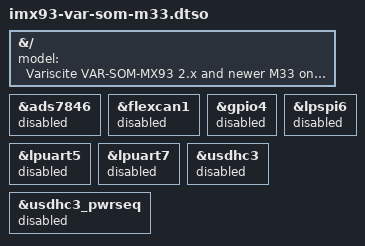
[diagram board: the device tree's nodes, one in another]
// SPDX-License-Identifier: (GPL-2.0+ OR MIT)
/*
 * Device tree overlay to support M33
 *
 * Copyright (C) 2026 Variscite Ltd. - https://www.variscite.com/
 *
 */

/dts-v1/;
/plugin/;

&{/} {
	model = "Variscite VAR-SOM-MX93 2.x and newer M33 on Symphony-Board";
};

/* Resistive touch controller uses GPIO4 */
&ads7846 {
    status = "disabled";
};

&flexcan1 {
	status = "disabled";
};

/* GPIO4 is used for M33 rled example */
&gpio4 {
    status = "disabled";
};

&lpspi6 {
    status = "disabled";
};

/* Disable BT since Wi-Fi is disabled and this allows JTAG pin access */
&lpuart5 {
    status = "disabled";
};

/* Used by M33 examples console/debug output */
&lpuart7 {
	status = "disabled";
};

/* Disable Wi-Fi as it uses a GPIO4 bank pin */
&usdhc3 {
    status = "disabled";
};

/* Wi-Fi disabled for m33 examples */
&usdhc3_pwrseq {
    status = "disabled";
};
